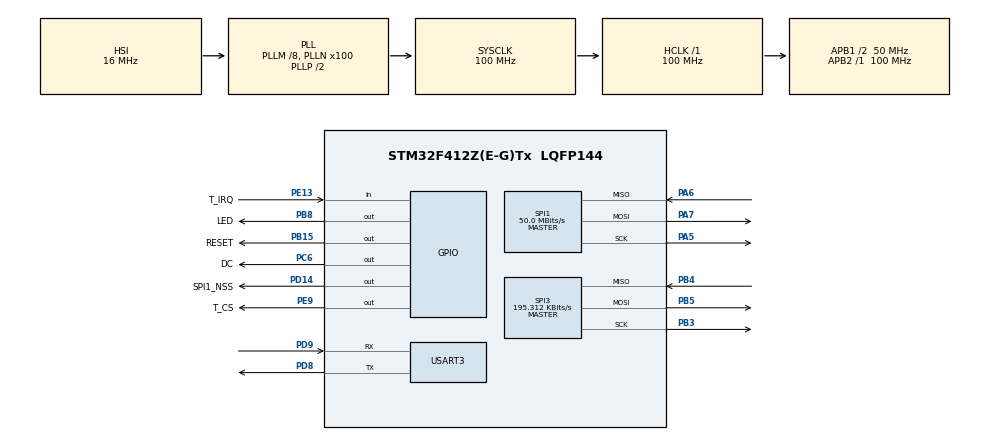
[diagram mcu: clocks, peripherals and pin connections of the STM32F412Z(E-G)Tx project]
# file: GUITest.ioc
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Dma.Request0=SPI1_TX
Dma.SPI1_TX.0.Direction=DMA_MEMORY_TO_PERIPH
Dma.SPI1_TX.0.FIFOMode=DMA_FIFOMODE_DISABLE
Dma.SPI1_TX.0.Instance=DMA2_Stream2
Dma.SPI1_TX.0.MemDataAlignment=DMA_MDATAALIGN_BYTE
Dma.SPI1_TX.0.MemInc=DMA_MINC_ENABLE
Dma.SPI1_TX.0.Mode=DMA_NORMAL
Dma.SPI1_TX.0.PeriphDataAlignment=DMA_PDATAALIGN_BYTE
Dma.SPI1_TX.0.PeriphInc=DMA_PINC_DISABLE
Dma.SPI1_TX.0.Priority=DMA_PRIORITY_LOW
FREERTOS.Tasks01=defaultTask,0,128,StartDefaultTask,Default,NULL,Dynamic,NULL,NULL
Mcu.Family=STM32F4
Mcu.Name=STM32F412Z(E-G)Tx
Mcu.Package=LQFP144
NVIC.DMA2_Stream2_IRQn=true\:5\:0\:false\:false\:true\:true\:false\:true
NVIC.PriorityGroup=NVIC_PRIORITYGROUP_4
NVIC.TIM8_TRG_COM_TIM14_IRQn=true\:0\:0\:false\:false\:true\:false\:false\:true
NVIC.TIM8_UP_TIM13_IRQn=true\:5\:0\:false\:false\:true\:true\:true\:true
NVIC.TimeBase=TIM8_TRG_COM_TIM14_IRQn
NVIC.TimeBaseIP=TIM14
NVIC.USART3_IRQn=true\:5\:0\:true\:false\:true\:true\:true\:true
PA13.Mode=Serial_Wire
PA13.Signal=SYS_JTMS-SWDIO
PA14.Mode=Serial_Wire
PA14.Signal=SYS_JTCK-SWCLK
PA5.Mode=Full_Duplex_Master
PA5.Signal=SPI1_SCK
PA6.Mode=Full_Duplex_Master
PA6.Signal=SPI1_MISO
PA7.Mode=Full_Duplex_Master
PA7.Signal=SPI1_MOSI
PB15.GPIO_Label=RESET
PB15.GPIO_Speed=GPIO_SPEED_FREQ_VERY_HIGH
PB15.PinState=GPIO_PIN_SET
PB15.Signal=GPIO_Output
PB3.Mode=Full_Duplex_Master
PB3.Signal=SPI3_SCK
PB4.Mode=Full_Duplex_Master
PB4.Signal=SPI3_MISO
PB5.Mode=Full_Duplex_Master
PB5.Signal=SPI3_MOSI
PB8.GPIO_Label=LED
PB8.GPIO_Speed=GPIO_SPEED_FREQ_VERY_HIGH
PB8.PinState=GPIO_PIN_SET
PB8.Signal=GPIO_Output
PC6.GPIO_Label=DC
PC6.GPIO_Speed=GPIO_SPEED_FREQ_VERY_HIGH
PC6.PinState=GPIO_PIN_SET
PC6.Signal=GPIO_Output
PD14.GPIO_Label=SPI1_NSS
PD14.GPIO_Speed=GPIO_SPEED_FREQ_VERY_HIGH
PD14.PinState=GPIO_PIN_SET
PD14.Signal=GPIO_Output
PD8.Mode=Asynchronous
PD8.Signal=USART3_TX
PD9.Mode=Asynchronous
PD9.Signal=USART3_RX
PE13.GPIO_Label=T_IRQ
PE13.Signal=GPIO_Input
PE9.GPIO_Label=T_CS
PE9.GPIO_Speed=GPIO_SPEED_FREQ_VERY_HIGH
PE9.PinState=GPIO_PIN_SET
PE9.Signal=GPIO_Output
ProjectManager.HeapSize=0x200
ProjectManager.StackSize=0x400
ProjectManager.TargetToolchain=STM32CubeIDE
RCC.AHBFreq_Value=100000000
RCC.APB1CLKDivider=RCC_HCLK_DIV2
RCC.APB1Freq_Value=50000000
RCC.APB1TimFreq_Value=100000000
RCC.APB2Freq_Value=100000000
RCC.APB2TimFreq_Value=100000000
RCC.CortexFreq_Value=100000000
RCC.HCLKFreq_Value=100000000
RCC.PLLM=8
RCC.PLLN=100
RCC.SYSCLKFreq_VALUE=100000000
RCC.SYSCLKSource=RCC_SYSCLKSOURCE_PLLCLK
RCC.USBFreq_Value=100000000
RCC.VCOOutputFreq_Value=200000000
SPI1.CalculateBaudRate=50.0 MBits/s
SPI1.Direction=SPI_DIRECTION_2LINES
SPI1.Mode=SPI_MODE_MASTER
SPI1.VirtualType=VM_MASTER
SPI3.BaudRatePrescaler=SPI_BAUDRATEPRESCALER_256
SPI3.CalculateBaudRate=195.312 KBits/s
SPI3.Direction=SPI_DIRECTION_2LINES
SPI3.Mode=SPI_MODE_MASTER
SPI3.VirtualType=VM_MASTER
STMicroelectronics.X-CUBE-TOUCHGFX.4.13.0.ApplicationCcGraphicsJjApplication=TouchGFXOoGenerator
STMicroelectronics.X-CUBE-TOUCHGFX.4.13.0.tgfx_custom_height=240
STMicroelectronics.X-CUBE-TOUCHGFX.4.13.0.tgfx_custom_width=320
TIM13.AutoReloadPreload=TIM_AUTORELOAD_PRELOAD_ENABLE
TIM13.Period=199
TIM13.Prescaler=49999
USART3.VirtualMode=VM_ASYNC
VP_CRC_VS_CRC.Mode=CRC_Activate
VP_FREERTOS_VS_CMSIS_V1.Mode=CMSIS_V1
VP_STMicroelectronics.X-CUBE-TOUCHGFX_VS_GraphicsJjApplication_4.13.0.Mode=GraphicsJjApplication
VP_SYS_VS_tim14.Mode=TIM14
VP_TIM13_VS_ClockSourceINT.Mode=Enable_Timer
board=custom

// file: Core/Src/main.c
/* USER CODE BEGIN Header */
/**
  ******************************************************************************
  * @file           : main.c
  * @brief          : Main program body
  ******************************************************************************
  * @attention
  *
  * <h2><center>&copy; Copyright (c) 2020 STMicroelectronics.
  * All rights reserved.</center></h2>
  *
  * This software component is licensed by ST under BSD 3-Clause license,
  * the "License"; You may not use this file except in compliance with the
  * License. You may obtain a copy of the License at:
  *                        opensource.org/licenses/BSD-3-Clause
  *
  ******************************************************************************
  */
/* USER CODE END Header */

#include "main.h"
#include "cmsis_os.h"
#include "app_touchgfx.h"

/* USER CODE BEGIN Includes */
#include "ili9341.h"
/* USER CODE END Includes */

CRC_HandleTypeDef hcrc;

SPI_HandleTypeDef hspi1;
SPI_HandleTypeDef hspi3;
DMA_HandleTypeDef hdma_spi1_tx;

TIM_HandleTypeDef htim13;

UART_HandleTypeDef huart3;

osThreadId defaultTaskHandle;

void SystemClock_Config(void);
static void MX_GPIO_Init(void);
static void MX_DMA_Init(void);
static void MX_CRC_Init(void);
static void MX_SPI1_Init(void);
static void MX_SPI3_Init(void);
static void MX_TIM13_Init(void);
static void MX_USART3_UART_Init(void);
void StartDefaultTask(void const * argument);

int main(void)
{

  /* MCU Configuration--------------------------------------------------------*/

  /* Reset of all peripherals, Initializes the Flash interface and the Systick. */
  HAL_Init();

  /* Configure the system clock */
  SystemClock_Config();

  /* Initialize all configured peripherals */
  MX_GPIO_Init();
  MX_DMA_Init();
  MX_CRC_Init();
  MX_SPI1_Init();
  MX_SPI3_Init();
  MX_TIM13_Init();
  MX_USART3_UART_Init();
  MX_TouchGFX_Init();
  /* USER CODE BEGIN 2 */
  ILI9341_Init();
  /* USER CODE END 2 */

  /* Create the thread(s) */
  /* definition and creation of defaultTask */
  osThreadDef(defaultTask, StartDefaultTask, osPriorityNormal, 0, 128);
  defaultTaskHandle = osThreadCreate(osThread(defaultTask), NULL);

  /* Start scheduler */
  osKernelStart();

  /* We should never get here as control is now taken by the scheduler */

  /* Infinite loop */
  while (1)
  {

  }
}

void SystemClock_Config(void)
{
  RCC_OscInitTypeDef RCC_OscInitStruct = {0};
  RCC_ClkInitTypeDef RCC_ClkInitStruct = {0};

  /** Configure the main internal regulator output voltage
  */
  __HAL_RCC_PWR_CLK_ENABLE();
  __HAL_PWR_VOLTAGESCALING_CONFIG(PWR_REGULATOR_VOLTAGE_SCALE1);
  /** Initializes the CPU, AHB and APB busses clocks
  */
  RCC_OscInitStruct.OscillatorType = RCC_OSCILLATORTYPE_HSI;
  RCC_OscInitStruct.HSIState = RCC_HSI_ON;
  RCC_OscInitStruct.HSICalibrationValue = RCC_HSICALIBRATION_DEFAULT;
  RCC_OscInitStruct.PLL.PLLState = RCC_PLL_ON;
  RCC_OscInitStruct.PLL.PLLSource = RCC_PLLSOURCE_HSI;
  RCC_OscInitStruct.PLL.PLLM = 8;
  RCC_OscInitStruct.PLL.PLLN = 100;
  RCC_OscInitStruct.PLL.PLLP = RCC_PLLP_DIV2;
  RCC_OscInitStruct.PLL.PLLQ = 2;
  RCC_OscInitStruct.PLL.PLLR = 2;
  if (HAL_RCC_OscConfig(&RCC_OscInitStruct) != HAL_OK)
  {
    Error_Handler();
  }
  /** Initializes the CPU, AHB and APB busses clocks
  */
  RCC_ClkInitStruct.ClockType = RCC_CLOCKTYPE_HCLK|RCC_CLOCKTYPE_SYSCLK
                              |RCC_CLOCKTYPE_PCLK1|RCC_CLOCKTYPE_PCLK2;
  RCC_ClkInitStruct.SYSCLKSource = RCC_SYSCLKSOURCE_PLLCLK;
  RCC_ClkInitStruct.AHBCLKDivider = RCC_SYSCLK_DIV1;
  RCC_ClkInitStruct.APB1CLKDivider = RCC_HCLK_DIV2;
  RCC_ClkInitStruct.APB2CLKDivider = RCC_HCLK_DIV1;

  if (HAL_RCC_ClockConfig(&RCC_ClkInitStruct, FLASH_LATENCY_3) != HAL_OK)
  {
    Error_Handler();
  }
}

static void MX_CRC_Init(void)
{

  hcrc.Instance = CRC;
  if (HAL_CRC_Init(&hcrc) != HAL_OK)
  {
    Error_Handler();
  }

}

static void MX_SPI1_Init(void)
{

  /* SPI1 parameter configuration*/
  hspi1.Instance = SPI1;
  hspi1.Init.Mode = SPI_MODE_MASTER;
  hspi1.Init.Direction = SPI_DIRECTION_2LINES;
  hspi1.Init.DataSize = SPI_DATASIZE_8BIT;
  hspi1.Init.CLKPolarity = SPI_POLARITY_LOW;
  hspi1.Init.CLKPhase = SPI_PHASE_1EDGE;
  hspi1.Init.NSS = SPI_NSS_SOFT;
  hspi1.Init.BaudRatePrescaler = SPI_BAUDRATEPRESCALER_2;
  hspi1.Init.FirstBit = SPI_FIRSTBIT_MSB;
  hspi1.Init.TIMode = SPI_TIMODE_DISABLE;
  hspi1.Init.CRCCalculation = SPI_CRCCALCULATION_DISABLE;
  hspi1.Init.CRCPolynomial = 10;
  if (HAL_SPI_Init(&hspi1) != HAL_OK)
  {
    Error_Handler();
  }

}

static void MX_SPI3_Init(void)
{

  /* SPI3 parameter configuration*/
  hspi3.Instance = SPI3;
  hspi3.Init.Mode = SPI_MODE_MASTER;
  hspi3.Init.Direction = SPI_DIRECTION_2LINES;
  hspi3.Init.DataSize = SPI_DATASIZE_8BIT;
  hspi3.Init.CLKPolarity = SPI_POLARITY_LOW;
  hspi3.Init.CLKPhase = SPI_PHASE_1EDGE;
  hspi3.Init.NSS = SPI_NSS_SOFT;
  hspi3.Init.BaudRatePrescaler = SPI_BAUDRATEPRESCALER_256;
  hspi3.Init.FirstBit = SPI_FIRSTBIT_MSB;
  hspi3.Init.TIMode = SPI_TIMODE_DISABLE;
  hspi3.Init.CRCCalculation = SPI_CRCCALCULATION_DISABLE;
  hspi3.Init.CRCPolynomial = 10;
  if (HAL_SPI_Init(&hspi3) != HAL_OK)
  {
    Error_Handler();
  }

}

static void MX_TIM13_Init(void)
{

  htim13.Instance = TIM13;
  htim13.Init.Prescaler = 49999;
  htim13.Init.CounterMode = TIM_COUNTERMODE_UP;
  htim13.Init.Period = 199;
  htim13.Init.ClockDivision = TIM_CLOCKDIVISION_DIV1;
  htim13.Init.AutoReloadPreload = TIM_AUTORELOAD_PRELOAD_ENABLE;
  if (HAL_TIM_Base_Init(&htim13) != HAL_OK)
  {
    Error_Handler();
  }
  /* USER CODE BEGIN TIM13_Init 2 */
  htim13.Instance->EGR |= TIM_EGR_UG;
  __HAL_TIM_CLEAR_IT(&htim13, TIM_IT_UPDATE);
  HAL_TIM_Base_Start_IT(&htim13);
  /* USER CODE END TIM13_Init 2 */

}

static void MX_USART3_UART_Init(void)
{

  huart3.Instance = USART3;
  huart3.Init.BaudRate = 115200;
  huart3.Init.WordLength = UART_WORDLENGTH_8B;
  huart3.Init.StopBits = UART_STOPBITS_1;
  huart3.Init.Parity = UART_PARITY_NONE;
  huart3.Init.Mode = UART_MODE_TX_RX;
  huart3.Init.HwFlowCtl = UART_HWCONTROL_NONE;
  huart3.Init.OverSampling = UART_OVERSAMPLING_16;
  if (HAL_UART_Init(&huart3) != HAL_OK)
  {
    Error_Handler();
  }

}

static void MX_DMA_Init(void)
{

  /* DMA controller clock enable */
  __HAL_RCC_DMA2_CLK_ENABLE();

  /* DMA interrupt init */
  /* DMA2_Stream2_IRQn interrupt configuration */
  HAL_NVIC_SetPriority(DMA2_Stream2_IRQn, 5, 0);
  HAL_NVIC_EnableIRQ(DMA2_Stream2_IRQn);

}

static void MX_GPIO_Init(void)
{
  GPIO_InitTypeDef GPIO_InitStruct = {0};

  /* GPIO Ports Clock Enable */
  __HAL_RCC_GPIOA_CLK_ENABLE();
  __HAL_RCC_GPIOE_CLK_ENABLE();
  __HAL_RCC_GPIOB_CLK_ENABLE();
  __HAL_RCC_GPIOD_CLK_ENABLE();
  __HAL_RCC_GPIOC_CLK_ENABLE();

  /*Configure GPIO pin Output Level */
  HAL_GPIO_WritePin(T_CS_GPIO_Port, T_CS_Pin, GPIO_PIN_SET);

  /*Configure GPIO pin Output Level */
  HAL_GPIO_WritePin(GPIOB, RESET_Pin|LED_Pin, GPIO_PIN_SET);

  /*Configure GPIO pin Output Level */
  HAL_GPIO_WritePin(SPI1_NSS_GPIO_Port, SPI1_NSS_Pin, GPIO_PIN_SET);

  /*Configure GPIO pin Output Level */
  HAL_GPIO_WritePin(DC_GPIO_Port, DC_Pin, GPIO_PIN_SET);

  /*Configure GPIO pin : T_CS_Pin */
  GPIO_InitStruct.Pin = T_CS_Pin;
  GPIO_InitStruct.Mode = GPIO_MODE_OUTPUT_PP;
  GPIO_InitStruct.Pull = GPIO_NOPULL;
  GPIO_InitStruct.Speed = GPIO_SPEED_FREQ_VERY_HIGH;
  HAL_GPIO_Init(T_CS_GPIO_Port, &GPIO_InitStruct);

  /*Configure GPIO pin : T_IRQ_Pin */
  GPIO_InitStruct.Pin = T_IRQ_Pin;
  GPIO_InitStruct.Mode = GPIO_MODE_INPUT;
  GPIO_InitStruct.Pull = GPIO_NOPULL;
  HAL_GPIO_Init(T_IRQ_GPIO_Port, &GPIO_InitStruct);

  /*Configure GPIO pins : RESET_Pin LED_Pin */
  GPIO_InitStruct.Pin = RESET_Pin|LED_Pin;
  GPIO_InitStruct.Mode = GPIO_MODE_OUTPUT_PP;
  GPIO_InitStruct.Pull = GPIO_NOPULL;
  GPIO_InitStruct.Speed = GPIO_SPEED_FREQ_VERY_HIGH;
  HAL_GPIO_Init(GPIOB, &GPIO_InitStruct);

  /*Configure GPIO pin : SPI1_NSS_Pin */
  GPIO_InitStruct.Pin = SPI1_NSS_Pin;
  GPIO_InitStruct.Mode = GPIO_MODE_OUTPUT_PP;
  GPIO_InitStruct.Pull = GPIO_NOPULL;
  GPIO_InitStruct.Speed = GPIO_SPEED_FREQ_VERY_HIGH;
  HAL_GPIO_Init(SPI1_NSS_GPIO_Port, &GPIO_InitStruct);

  /*Configure GPIO pin : DC_Pin */
  GPIO_InitStruct.Pin = DC_Pin;
  GPIO_InitStruct.Mode = GPIO_MODE_OUTPUT_PP;
  GPIO_InitStruct.Pull = GPIO_NOPULL;
  GPIO_InitStruct.Speed = GPIO_SPEED_FREQ_VERY_HIGH;
  HAL_GPIO_Init(DC_GPIO_Port, &GPIO_InitStruct);

}

void StartDefaultTask(void const * argument)
{
  /* USER CODE BEGIN 5 */
	MX_TouchGFX_Process();
  /* USER CODE END 5 */
}

#if 0
// Kotetsu
void HAL_TIM_PeriodElapsedCallback(TIM_HandleTypeDef *htim)
{
  if (htim->Instance == TIM14) {
    HAL_IncTick();
  }
}
#endif

void Error_Handler(void)
{
}

/************************ (C) COPYRIGHT STMicroelectronics *****END OF FILE****/
